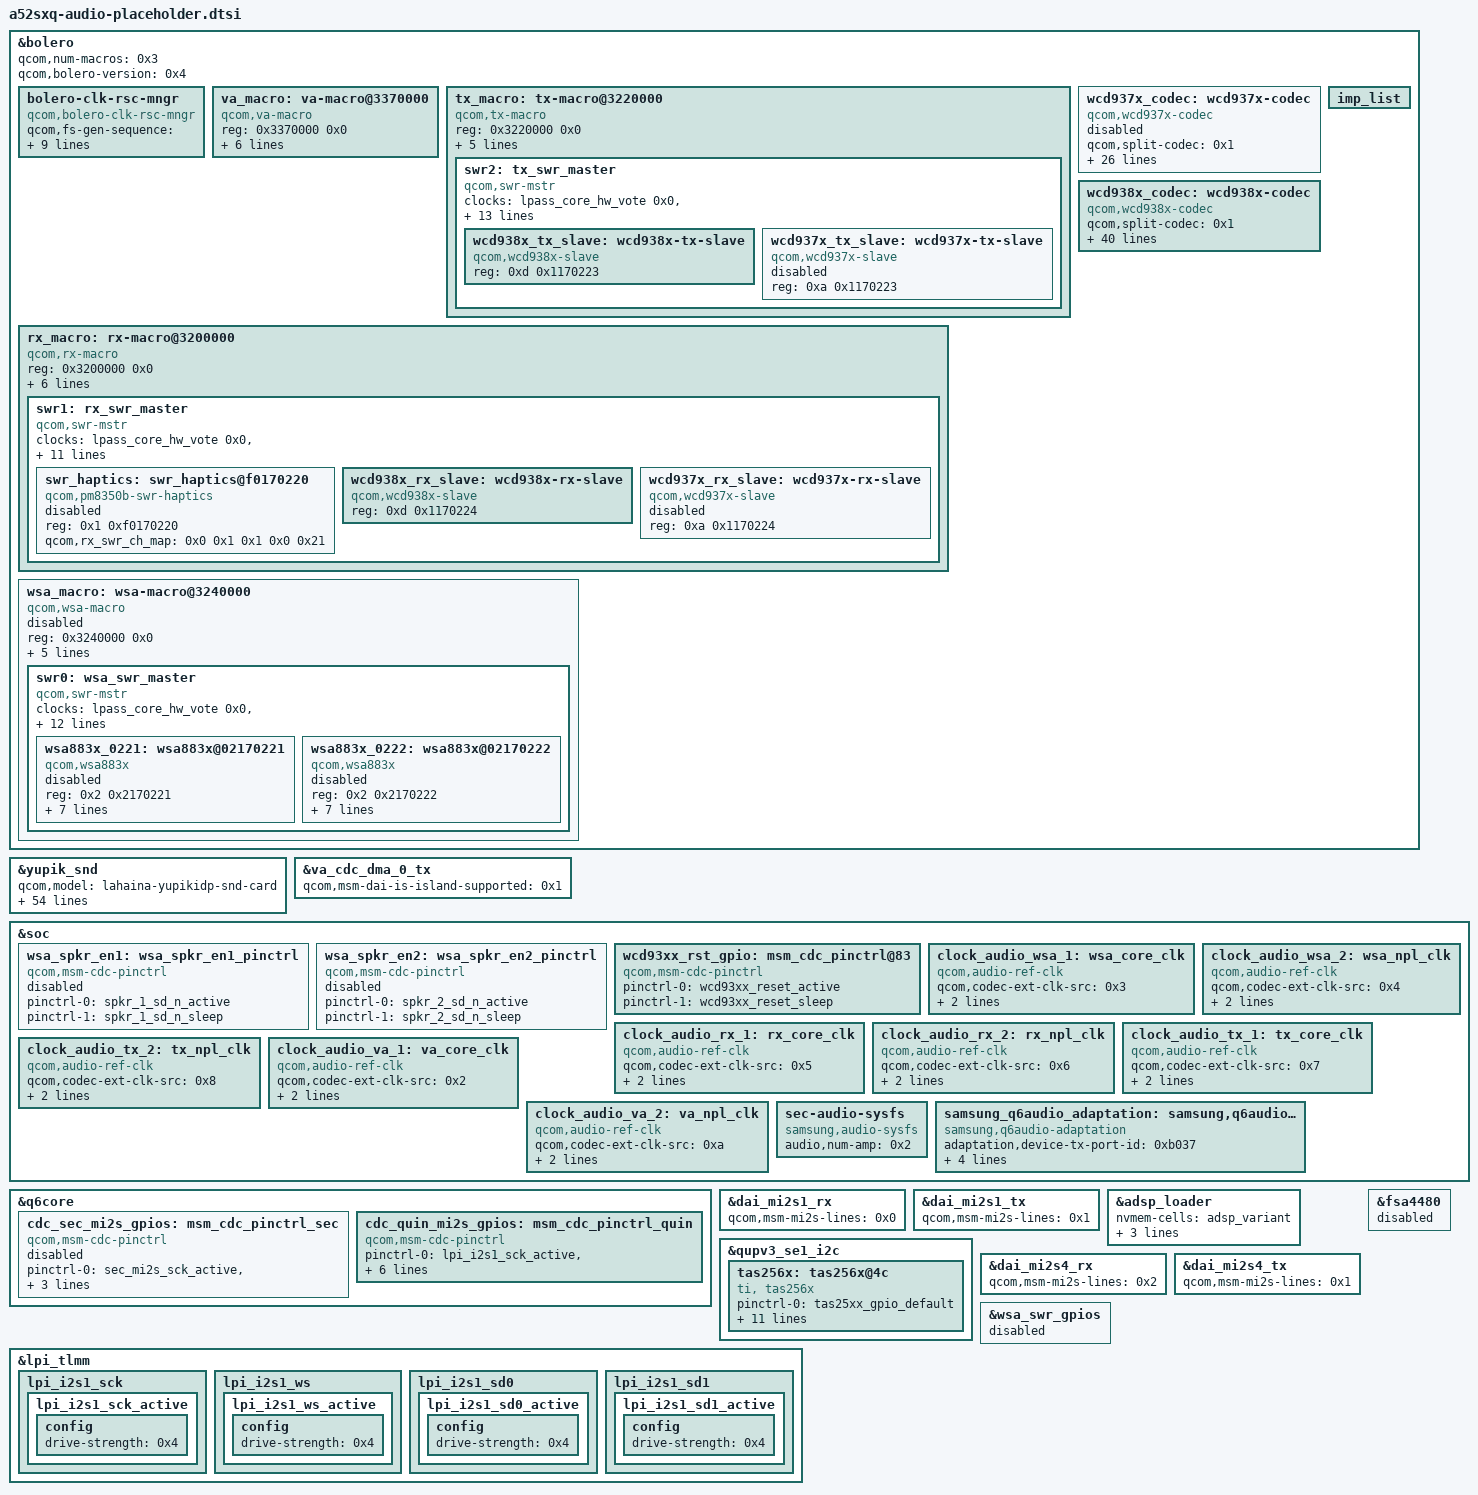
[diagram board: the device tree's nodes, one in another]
// SPDX-License-Identifier: GPL-2.0
/*
 * a52sxq board description for the Qualcomm 6.12 yupik base: audio (owned by agent 'audio': TODO-binding placeholder)
 * GENERATED by tools/gen.py from the phone's stock dtbo (5.4 bindings, values verbatim).
 * Do not edit: hand-written 6.12 changes live in a52sxq-bsp612-fixups.dtsi.
 */

&bolero {	/* TODO-binding: label not in the 6.12 base, placeholder */
	qcom,num-macros = <0x3>;
	qcom,bolero-version = <0x4>;
	#address-cells = <0x1>;
	#size-cells = <0x1>;

	bolero-clk-rsc-mngr {
		compatible = "qcom,bolero-clk-rsc-mngr";
		qcom,fs-gen-sequence = <0x3000 0x1 0x1 0x3004 0x3 0x3 0x3004 0x3 0x1 0x3080 0x2 0x2>;
		qcom,rx_mclk_mode_muxsel = <0x33240d8>;
		qcom,wsa_mclk_mode_muxsel = <0x33220d8>;
		qcom,va_mclk_mode_muxsel = <0x33a0000>;
		clock-names = "tx_core_clk", "tx_npl_clk", "rx_core_clk", "rx_npl_clk", "wsa_core_clk", "wsa_npl_clk", "va_core_clk", "va_npl_clk";
		clocks = <&clock_audio_tx_1 0x0 &clock_audio_tx_2 0x0 &clock_audio_rx_1 0x0 &clock_audio_rx_2 0x0 &clock_audio_wsa_1 0x0 &clock_audio_wsa_2 0x0 &clock_audio_va_1 0x0 &clock_audio_va_2 0x0>;
	};

	va_macro: va-macro@3370000 {
		compatible = "qcom,va-macro";
		reg = <0x3370000 0x0>;
		clock-names = "lpass_audio_hw_vote";
		clocks = <&lpass_audio_hw_vote 0x0>;
		qcom,va-vdd-micb-voltage = <0x1b7740 0x1b7740>;
		qcom,va-vdd-micb-current = <0x2bc0>;
		qcom,va-dmic-sample-rate = <0x927c0>;
		qcom,default-clk-id = <0x0>;
		qcom,is-used-swr-gpio = <0x0>;
	};

	tx_macro: tx-macro@3220000 {
		compatible = "qcom,tx-macro";
		reg = <0x3220000 0x0>;
		clock-names = "tx_core_clk", "tx_npl_clk";
		clocks = <&clock_audio_tx_1 0x0 &clock_audio_tx_2 0x0>;
		qcom,tx-swr-gpios = <&tx_swr_gpios>;
		qcom,tx-dmic-sample-rate = <0x249f00>;
		qcom,disable-afe-wakeup-event-listener = <0x1>;

		swr2: tx_swr_master {
			compatible = "qcom,swr-mstr";
			#address-cells = <0x2>;
			#size-cells = <0x0>;
			clock-names = "lpass_core_hw_vote", "lpass_audio_hw_vote";
			clocks = <&lpass_core_hw_vote 0x0 &lpass_audio_hw_vote 0x0>;
			qcom,swr_master_id = <0x3>;
			qcom,swrm-hctl-reg = <0x32a90a8>;
			qcom,mipi-sdw-block-packing-mode = <0x1>;
			swrm-io-base = <0x3230000 0x0>;
			interrupts-extended = <&intc 0x0 0x1f0 0x4 &pdc 0x82 0x4>;
			interrupt-names = "swr_master_irq", "swr_wake_irq";
			qcom,swr-num-ports = <0x3>;
			qcom,swr-port-mapping = <0x1 0x22 0x1 0x1 0x23 0x2 0x1 0x24 0x4 0x1 0x25 0x8 0x2 0x26 0x1 0x2 0x27 0x2 0x2 0x28 0x4 0x2 0x29 0x8 0x3 0x2a 0x1 0x3 0x2b 0x2 0x3 0x2c 0x4 0x3 0x2d 0x8>;
			qcom,swr-num-dev = <0x1>;
			qcom,swr-clock-stop-mode0 = <0x1>;
			qcom,swr-mstr-irq-wakeup-capable = <0x1>;

			wcd938x_tx_slave: wcd938x-tx-slave {
				status = "okay";
				compatible = "qcom,wcd938x-slave";
				reg = <0xd 0x1170223>;
			};

			wcd937x_tx_slave: wcd937x-tx-slave {
				compatible = "qcom,wcd937x-slave";
				reg = <0xa 0x1170223>;
				status = "disabled";
			};
		};
	};

	rx_macro: rx-macro@3200000 {
		compatible = "qcom,rx-macro";
		reg = <0x3200000 0x0>;
		clock-names = "rx_core_clk", "rx_npl_clk";
		clocks = <&clock_audio_rx_1 0x0 &clock_audio_rx_2 0x0>;
		qcom,rx-swr-gpios = <&rx_swr_gpios>;
		qcom,rx_mclk_mode_muxsel = <0x33240d8>;
		qcom,rx-bcl-pmic-params = [00 03 48];
		qcom,default-clk-id = <0x0>;

		swr1: rx_swr_master {
			compatible = "qcom,swr-mstr";
			#address-cells = <0x2>;
			#size-cells = <0x0>;
			clock-names = "lpass_core_hw_vote", "lpass_audio_hw_vote";
			clocks = <&lpass_core_hw_vote 0x0 &lpass_audio_hw_vote 0x0>;
			qcom,swr_master_id = <0x2>;
			qcom,swrm-hctl-reg = <0x32a90a0>;
			qcom,mipi-sdw-block-packing-mode = <0x1>;
			swrm-io-base = <0x3210000 0x0>;
			interrupts = <0x0 0x9b 0x4>;
			interrupt-names = "swr_master_irq";
			qcom,swr-num-ports = <0x6>;
			qcom,swr-port-mapping = <0x1 0x9 0x1 0x1 0xa 0x2 0x2 0xd 0x1 0x3 0xb 0x1 0x3 0xc 0x2 0x4 0xe 0x1 0x5 0xf 0x1 0x5 0x10 0x2 0x6 0x21 0x1>;
			qcom,swr-num-dev = <0x2>;
			qcom,swr-clock-stop-mode0 = <0x1>;

			swr_haptics: swr_haptics@f0170220 {
				status = "disabled";
				compatible = "qcom,pm8350b-swr-haptics";
				reg = <0x1 0xf0170220>;
				qcom,rx_swr_ch_map = <0x0 0x1 0x1 0x0 0x21>;
			};

			wcd938x_rx_slave: wcd938x-rx-slave {
				status = "okay";
				compatible = "qcom,wcd938x-slave";
				reg = <0xd 0x1170224>;
			};

			wcd937x_rx_slave: wcd937x-rx-slave {
				compatible = "qcom,wcd937x-slave";
				reg = <0xa 0x1170224>;
				status = "disabled";
			};
		};
	};

	wsa_macro: wsa-macro@3240000 {
		compatible = "qcom,wsa-macro";
		reg = <0x3240000 0x0>;
		clock-names = "wsa_core_clk", "wsa_npl_clk";
		clocks = <&clock_audio_wsa_1 0x0 &clock_audio_wsa_2 0x0>;
		qcom,wsa-swr-gpios = <&wsa_swr_gpios>;
		qcom,wsa-bcl-pmic-params = [00 03 48];
		qcom,default-clk-id = <0x0>;
		status = "disabled";

		swr0: wsa_swr_master {
			compatible = "qcom,swr-mstr";
			#address-cells = <0x2>;
			#size-cells = <0x0>;
			clock-names = "lpass_core_hw_vote", "lpass_audio_hw_vote";
			clocks = <&lpass_core_hw_vote 0x0 &lpass_audio_hw_vote 0x0>;
			qcom,swr_master_id = <0x1>;
			qcom,swrm-hctl-reg = <0x32a90b0>;
			qcom,mipi-sdw-block-packing-mode = <0x0>;
			swrm-io-base = <0x3250000 0x0>;
			interrupts = <0x0 0xaa 0x4>;
			interrupt-names = "swr_master_irq";
			qcom,swr-num-ports = <0x8>;
			qcom,swr-clock-stop-mode0 = <0x1>;
			qcom,swr-port-mapping = <0x1 0x1 0x1 0x2 0x2 0xf 0x3 0x3 0x3 0x4 0x5 0x1 0x5 0x6 0xf 0x6 0x7 0x3 0x7 0x4 0x3 0x8 0x8 0x3>;
			qcom,swr-num-dev = <0x2>;
			qcom,dynamic-port-map-supported = <0x0>;

			wsa883x_0221: wsa883x@02170221 {
				compatible = "qcom,wsa883x";
				reg = <0x2 0x2170221>;
				qcom,spkr-sd-n-node = <&wsa_spkr_en1>;
				qcom,bolero-handle = <&bolero>;
				cdc-vdd-1p8-supply = <&L18B>;
				qcom,cdc-vdd-1p8-voltage = <0x1b7740 0x1b7740>;
				qcom,cdc-vdd-1p8-current = <0x4e20>;
				qcom,cdc-static-supplies = "cdc-vdd-1p8";
				qcom,wsa-prefix = "SpkrLeft";
				status = "disabled";
			};

			wsa883x_0222: wsa883x@02170222 {
				compatible = "qcom,wsa883x";
				reg = <0x2 0x2170222>;
				qcom,spkr-sd-n-node = <&wsa_spkr_en2>;
				qcom,bolero-handle = <&bolero>;
				cdc-vdd-1p8-supply = <&L18B>;
				qcom,cdc-vdd-1p8-voltage = <0x1b7740 0x1b7740>;
				qcom,cdc-vdd-1p8-current = <0x4e20>;
				qcom,cdc-static-supplies = "cdc-vdd-1p8";
				qcom,wsa-prefix = "SpkrRight";
				status = "disabled";
			};
		};
	};

	wcd937x_codec: wcd937x-codec {
		compatible = "qcom,wcd937x-codec";
		qcom,split-codec = <0x1>;
		qcom,rx_swr_ch_map = <0x0 0x9 0x1 0x0 0x9 0x0 0xa 0x2 0x0 0xa 0x1 0xd 0x1 0x0 0xd 0x2 0xb 0x1 0x0 0xb 0x2 0xc 0x2 0x0 0xc 0x3 0xe 0x1 0x0 0xe 0x4 0xf 0x1 0x0 0xf 0x4 0x10 0x2 0x0 0x10>;
		qcom,tx_swr_ch_map = <0x0 0x12 0x1 0x0 0x22 0x1 0x13 0x1 0x0 0x26 0x1 0x14 0x2 0x0 0x27 0x2 0x16 0x1 0x0 0x25 0x2 0x17 0x2 0x0 0x26 0x2 0x11 0x4 0x0 0x27 0x3 0x18 0x1 0x0 0x28 0x3 0x19 0x2 0x0 0x29 0x3 0x1a 0x4 0x0 0x2a 0x3 0x1b 0x8 0x0 0x2b>;
		qcom,wcd-rst-gpio-node = <&wcd93xx_rst_gpio>;
		qcom,rx-slave = <&wcd937x_rx_slave>;
		qcom,tx-slave = <&wcd937x_tx_slave>;
		cdc-vdd-rxtx-supply = <&L18B>;
		qcom,cdc-vdd-rxtx-voltage = <0x1b7740 0x1b7740>;
		qcom,cdc-vdd-rxtx-current = <0x7530>;
		cdc-vddpx-supply = <&L18B>;
		qcom,cdc-vddpx-voltage = <0x1b7740 0x1b7740>;
		qcom,cdc-vddpx-current = <0x7530>;
		cdc-vdd-buck-supply = <&L17B>;
		qcom,cdc-vdd-buck-voltage = <0x1b7740 0x1b7740>;
		qcom,cdc-vdd-buck-current = <0x927c0>;
		cdc-vdd-mic-bias-supply = <&BOB>;
		qcom,cdc-vdd-mic-bias-voltage = <0x324b00 0x324b00>;
		qcom,cdc-vdd-mic-bias-current = <0xafc8>;
		qcom,cdc-micbias1-mv = <0x708>;
		qcom,cdc-micbias2-mv = <0x708>;
		qcom,cdc-micbias3-mv = <0x708>;
		qcom,cdc-static-supplies = "cdc-vdd-rxtx", "cdc-vddpx", "cdc-vdd-mic-bias";
		qcom,cdc-on-demand-supplies = "cdc-vdd-buck";
		status = "disabled";
	};

	wcd938x_codec: wcd938x-codec {
		status = "ok";
		compatible = "qcom,wcd938x-codec";
		qcom,split-codec = <0x1>;
		qcom,rx_swr_ch_map = <0x0 0x9 0x1 0x0 0x9 0x0 0xa 0x2 0x0 0xa 0x1 0xd 0x1 0x0 0xd 0x2 0xb 0x1 0x0 0xb 0x2 0xc 0x2 0x0 0xc 0x3 0xe 0x1 0x0 0xe 0x4 0xf 0x1 0x0 0xf 0x4 0x10 0x2 0x0 0x10>;
		qcom,tx_swr_ch_map = <0x0 0x12 0x1 0x0 0x22 0x0 0x13 0x2 0x0 0x23 0x1 0x14 0x1 0x0 0x26 0x1 0x15 0x2 0x0 0x27 0x2 0x16 0x1 0x0 0x24 0x2 0x17 0x2 0x0 0x25 0x2 0x11 0x4 0x0 0x28 0x2 0x18 0x4 0x0 0x28 0x2 0x19 0x8 0x0 0x29 0x3 0x1a 0x1 0x0 0x2a 0x3 0x1b 0x2 0x0 0x2b 0x3 0x1c 0x4 0x0 0x2c 0x3 0x1d 0x8 0x0 0x2d>;
		qcom,wcd-rst-gpio-node = <&wcd93xx_rst_gpio>;
		qcom,rx-slave = <&wcd938x_rx_slave>;
		qcom,tx-slave = <&wcd938x_tx_slave>;
		cdc-vdd-rxtx-supply = <&L18B>;
		qcom,cdc-vdd-rxtx-voltage = <0x1b7740 0x1b7740>;
		qcom,cdc-vdd-rxtx-current = <0x7530>;
		cdc-vddpx-supply = <&L18B>;
		qcom,cdc-vddpx-voltage = <0x1b7740 0x1b7740>;
		qcom,cdc-vddpx-current = <0x7530>;
		cdc-vdd-buck-supply = <&L17B>;
		qcom,cdc-vdd-buck-voltage = <0x1b7740 0x1b7740>;
		qcom,cdc-vdd-buck-current = <0x927c0>;
		cdc-vdd-mic-bias-supply = <&BOB>;
		qcom,cdc-vdd-mic-bias-voltage = <0x324b00 0x324b00>;
		qcom,cdc-vdd-mic-bias-current = <0x7530>;
		qcom,cdc-micbias1-mv = <0x708>;
		qcom,cdc-micbias2-mv = <0xaf0>;
		qcom,cdc-micbias3-mv = <0x708>;
		qcom,cdc-micbias4-mv = <0x708>;
		qcom,cdc-static-supplies = "cdc-vdd-rxtx", "cdc-vddpx", "cdc-vdd-mic-bias";
		qcom,cdc-on-demand-supplies = "cdc-vdd-buck";
		mbhc-button-thres = <&det_zones 0xd 0x3f &det_zones 0x58 0x8a &det_zones 0x8a 0x8a &det_zones 0xe1 0xe1 &det_zones 0x1c2 0x1c2 &det_zones 0x1c2 0x26c &det_zones 0x1c2 0x26c &det_zones 0x1c2 0x26c>;
		imp-table = <&imp_list 0x0 0x5 0x6 &imp_list 0x6 0x17 0x8 &imp_list 0x18 0x26 0x7 &imp_list 0x27 0x64 0x6 &imp_list 0x65 0xa0 0xa &imp_list 0xa1 0x190 0xb &imp_list 0x191 0x7d0 0xb &imp_list 0x7d1 0x7fffffff 0x6>;
	};

	imp_list: imp_list {
		#list-imp-cells = <0x3>;
	};
};

&yupik_snd {	/* TODO-binding: label not in the 6.12 base, placeholder */
	qcom,model = "lahaina-yupikidp-snd-card";
	qcom,msm-mi2s-master = <0x1 0x1 0x1 0x1 0x1 0x1>;
	qcom,tdm-max-slots = <0x8>;
	qcom,wcd-disabled = <0x0>;
	qcom,audio-routing = "AMIC1", "Analog Mic1", "Analog Mic1", "MIC BIAS1", "AMIC2", "Analog Mic2", "Analog Mic2", "MIC BIAS2", "AMIC3", "Analog Mic3", "Analog Mic3", "MIC BIAS1", "AMIC4", "Analog Mic4", "Analog Mic4", "MIC BIAS3", "IN1_HPHL", "HPHL_OUT", "IN2_HPHR", "HPHR_OUT", "RX_TX DEC0_INP", "TX DEC0 MUX", "RX_TX DEC1_INP", "TX DEC1 MUX", "RX_TX DEC2_INP", "TX DEC2 MUX", "RX_TX DEC3_INP", "TX DEC3 MUX", "TX SWR_INPUT", "WCD_TX_OUTPUT", "VA SWR_INPUT", "VA_SWR_CLK", "VA SWR_INPUT", "WCD_TX_OUTPUT", "VA_AIF1 CAP", "VA_SWR_CLK", "VA_AIF2 CAP", "VA_SWR_CLK", "VA_AIF3 CAP", "VA_SWR_CLK";
	qcom,msm-mbhc-hphl-swh = <0x1>;
	qcom,msm-mbhc-gnd-swh = <0x1>;
	qcom,swr-dmic-max-devs = <0x0>;
	qcom,cdc-dmic01-gpios;
	qcom,cdc-dmic23-gpios;
	qcom,cdc-dmic45-gpios;
	qcom,sec-mi2s-gpios;
	asoc-codec = <&stub_codec &bolero &wcd938x_codec>;
	asoc-codec-names = "msm-stub-codec.1", "bolero_codec", "wcd938x_codec";
	qcom,wsa-max-devs = <0x0>;
	qcom,cps_reg_phy_addr = <0x3250300 0x3250304 0x3250318>;
	qcom,cps_wsa_vbatt_temp_reg_addr = <0x3429 0x3422>;
	qcom,cps_threshold_levels = <0x94 0xa8>;
	qcom,cps_normal_values = <0x8e 0x8f 0x8f>;
	qcom,cps_lower1_values = <0x10 0xd0 0xd0>;
	qcom,cps_lower2_values = <0xf 0xf 0x18>;
	qcom,msm_audio_ssr_devs = <&audio_apr &q6core &lpi_tlmm &bolero>;
	qcom,ext-disp-audio-rx = <0x0>;
	asoc-platform = <&pcm0 &pcm1 &pcm2 &voip &voice &loopback &compress &hostless &afe &lsm &routing &compr &pcm_noirq &samsung_q6audio_adaptation>;
	asoc-platform-names = "msm-pcm-dsp.0", "msm-pcm-dsp.1", "msm-pcm-dsp.2", "msm-voip-dsp", "msm-pcm-voice", "msm-pcm-loopback", "msm-compress-dsp", "msm-pcm-hostless", "msm-pcm-afe", "msm-lsm-client", "msm-pcm-routing", "msm-compr-dsp", "msm-pcm-dsp-noirq", "q6audio-adaptation";
	qcom,msm-mbhc-hs-mic-max-threshold-mv = <0x270f>;
	qcom,msm-mbhc-hs-mic-min-threshold-mv = <0x280>;
	qcom,quin-mi2s-gpios = <&cdc_quin_mi2s_gpios>;
	fsa4480-i2c-handle;
	qcom,msm-mbhc-gnd-det = <0x1>;
};

&va_cdc_dma_0_tx {	/* TODO-binding: label not in the 6.12 base, placeholder */
	qcom,msm-dai-is-island-supported = <0x1>;
};

&soc {

	wsa_spkr_en1: wsa_spkr_en1_pinctrl {
		compatible = "qcom,msm-cdc-pinctrl";
		pinctrl-names = "aud_active", "aud_sleep";
		pinctrl-0 = <&spkr_1_sd_n_active>;
		pinctrl-1 = <&spkr_1_sd_n_sleep>;
		status = "disabled";
	};

	wsa_spkr_en2: wsa_spkr_en2_pinctrl {
		compatible = "qcom,msm-cdc-pinctrl";
		pinctrl-names = "aud_active", "aud_sleep";
		pinctrl-0 = <&spkr_2_sd_n_active>;
		pinctrl-1 = <&spkr_2_sd_n_sleep>;
		status = "disabled";
	};

	wcd93xx_rst_gpio: msm_cdc_pinctrl@83 {
		compatible = "qcom,msm-cdc-pinctrl";
		pinctrl-names = "aud_active", "aud_sleep";
		pinctrl-0 = <&wcd93xx_reset_active>;
		pinctrl-1 = <&wcd93xx_reset_sleep>;
	};

	clock_audio_wsa_1: wsa_core_clk {
		compatible = "qcom,audio-ref-clk";
		qcom,codec-ext-clk-src = <0x3>;
		qcom,codec-lpass-ext-clk-freq = <0x124f800>;
		qcom,codec-lpass-clk-id = <0x309>;
		#clock-cells = <0x1>;
	};

	clock_audio_wsa_2: wsa_npl_clk {
		compatible = "qcom,audio-ref-clk";
		qcom,codec-ext-clk-src = <0x4>;
		qcom,codec-lpass-ext-clk-freq = <0x124f800>;
		qcom,codec-lpass-clk-id = <0x30a>;
		#clock-cells = <0x1>;
	};

	clock_audio_rx_1: rx_core_clk {
		compatible = "qcom,audio-ref-clk";
		qcom,codec-ext-clk-src = <0x5>;
		qcom,codec-lpass-ext-clk-freq = <0x1588800>;
		qcom,codec-lpass-clk-id = <0x30e>;
		#clock-cells = <0x1>;
	};

	clock_audio_rx_2: rx_npl_clk {
		compatible = "qcom,audio-ref-clk";
		qcom,codec-ext-clk-src = <0x6>;
		qcom,codec-lpass-ext-clk-freq = <0x1588800>;
		qcom,codec-lpass-clk-id = <0x30f>;
		#clock-cells = <0x1>;
	};

	clock_audio_tx_1: tx_core_clk {
		compatible = "qcom,audio-ref-clk";
		qcom,codec-ext-clk-src = <0x7>;
		qcom,codec-lpass-ext-clk-freq = <0x124f800>;
		qcom,codec-lpass-clk-id = <0x30c>;
		#clock-cells = <0x1>;
	};

	clock_audio_tx_2: tx_npl_clk {
		compatible = "qcom,audio-ref-clk";
		qcom,codec-ext-clk-src = <0x8>;
		qcom,codec-lpass-ext-clk-freq = <0x124f800>;
		qcom,codec-lpass-clk-id = <0x30d>;
		#clock-cells = <0x1>;
	};

	clock_audio_va_1: va_core_clk {
		compatible = "qcom,audio-ref-clk";
		qcom,codec-ext-clk-src = <0x2>;
		qcom,codec-lpass-ext-clk-freq = <0x124f800>;
		qcom,codec-lpass-clk-id = <0x30b>;
		#clock-cells = <0x1>;
	};

	clock_audio_va_2: va_npl_clk {
		compatible = "qcom,audio-ref-clk";
		qcom,codec-ext-clk-src = <0xa>;
		qcom,codec-lpass-ext-clk-freq = <0x124f800>;
		qcom,codec-lpass-clk-id = <0x310>;
		#clock-cells = <0x1>;
	};

	sec-audio-sysfs {
		compatible = "samsung,audio-sysfs";
		status = "okay";
		audio,num-amp = <0x2>;
	};

	samsung_q6audio_adaptation: samsung,q6audio-adaptation {
		compatible = "samsung,q6audio-adaptation";
		adaptation,device-tx-port-id = <0xb037>;
		adaptation,spk-rx-port-id = <0x1016>;
		adaptation,usb-rx-port-id = <0x7000>;
		adaptation,bt-rx-port-id = <0x400e>;
		adaptation,headset-rx-port-id = <0xb030>;
	};
};

&q6core {	/* TODO-binding: label not in the 6.12 base, placeholder */

	cdc_sec_mi2s_gpios: msm_cdc_pinctrl_sec {
		compatible = "qcom,msm-cdc-pinctrl";
		pinctrl-names = "aud_active", "aud_sleep";
		pinctrl-0 = <&sec_mi2s_sck_active &sec_mi2s_ws_active &sec_mi2s_sd0_active>;
		pinctrl-1 = <&sec_mi2s_sck_sleep &sec_mi2s_ws_sleep &sec_mi2s_sd0_sleep>;
		#gpio-cells = <0x0>;
		status = "disabled";
	};

	cdc_quin_mi2s_gpios: msm_cdc_pinctrl_quin {
		compatible = "qcom,msm-cdc-pinctrl";
		pinctrl-names = "aud_active", "aud_sleep";
		pinctrl-0 = <&lpi_i2s1_sck_active &lpi_i2s1_ws_active &lpi_i2s1_sd0_active &lpi_i2s1_sd1_active>;
		pinctrl-1 = <&lpi_i2s1_sck_sleep &lpi_i2s1_ws_sleep &lpi_i2s1_sd0_sleep &lpi_i2s1_sd1_sleep>;
		qcom,lpi-gpios;
		#gpio-cells = <0x0>;
	};
};

&dai_mi2s1_rx {	/* TODO-binding: label not in the 6.12 base, placeholder */
	qcom,msm-mi2s-lines = <0x0>;
};

&dai_mi2s1_tx {	/* TODO-binding: label not in the 6.12 base, placeholder */
	qcom,msm-mi2s-lines = <0x1>;
};

&adsp_loader {	/* TODO-binding: label not in the 6.12 base, placeholder */
	nvmem-cells = <&adsp_variant>;
	nvmem-cell-names = "adsp_variant";
	adsp-fw-names = "adsp2";
	adsp-fw-bit-values = <0x4>;
};

&qupv3_se1_i2c {

	tas256x: tas256x@4c {
		status = "ok";
		#sound-dai-cells = <0x0>;
		compatible = "ti, tas256x";
		pinctrl-names = "default";
		pinctrl-0 = <&tas25xx_gpio_default>;
		reg = <0x4c>;
		ti,reset-gpio = <&tlmm 0x3f 0x0>;
		ti,irq-gpio = <&tlmm 0x37 0x0>;
		ti,left-channel = <0x4d>;
		ti,right-channel = <0x4c>;
		ti,channels = <0x2>;
		ti,iv-width = <0x8>;
		ti,vbat-mon = <0x1>;
		ti,port_id = <0x1016>;
		ti,module_id_rx = <0x1000fc00>;
		ti,module_id_tx = <0x1000fd00>;
	};
};

&dai_mi2s4_rx {	/* TODO-binding: label not in the 6.12 base, placeholder */
	qcom,msm-mi2s-lines = <0x2>;
};

&dai_mi2s4_tx {	/* TODO-binding: label not in the 6.12 base, placeholder */
	qcom,msm-mi2s-lines = <0x1>;
};

&fsa4480 {
	status = "disabled";
};

&wsa_swr_gpios {	/* TODO-binding: label not in the 6.12 base, placeholder */
	status = "disabled";
};

&lpi_tlmm {	/* TODO-binding: label not in the 6.12 base, placeholder */

	lpi_i2s1_sck {

		lpi_i2s1_sck_active: lpi_i2s1_sck_active {

			config {
				drive-strength = <0x4>;
			};
		};
	};

	lpi_i2s1_ws {

		lpi_i2s1_ws_active: lpi_i2s1_ws_active {

			config {
				drive-strength = <0x4>;
			};
		};
	};

	lpi_i2s1_sd0 {

		lpi_i2s1_sd0_active: lpi_i2s1_sd0_active {

			config {
				drive-strength = <0x4>;
			};
		};
	};

	lpi_i2s1_sd1 {

		lpi_i2s1_sd1_active: lpi_i2s1_sd1_active {

			config {
				drive-strength = <0x4>;
			};
		};
	};
};

